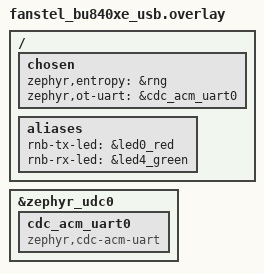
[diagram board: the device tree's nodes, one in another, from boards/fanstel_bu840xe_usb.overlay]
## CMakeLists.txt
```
# SPDX-License-Identifier: Apache-2.0

cmake_minimum_required(VERSION 3.20.0)

set(OT_NCP_VENDOR_HOOK_SOURCE_DIR ${CMAKE_CURRENT_SOURCE_DIR})

list(APPEND DTS_ROOT ${CMAKE_CURRENT_SOURCE_DIR}/../..)
list(APPEND BOARD_ROOT ${CMAKE_CURRENT_SOURCE_DIR}/../..)

string(REPLACE " " ";" OVERLAY_CONFIG_LIST "${OVERLAY_CONFIG}")
if("overlay-ot-rnb.conf" IN_LIST OVERLAY_CONFIG_LIST)
  include(${CMAKE_CURRENT_SOURCE_DIR}/../common/CMakeLists.txt)
endif()

if("overlay-usb-rnb.conf" IN_LIST OVERLAY_CONFIG_LIST)
  list(APPEND DTC_OVERLAY_FILE ${CMAKE_CURRENT_SOURCE_DIR}/boards/${BOARD}_usb.overlay)
endif()

include(CheckGit.cmake)
CheckCoprocessorGitSetup()

find_package(Zephyr REQUIRED HINTS $ENV{ZEPHYR_BASE})
project(coprocessor)

target_sources(app PRIVATE src/main.c src/nrf_802154_radio_wrapper.c ${CMAKE_BINARY_DIR}/generated/rnb_coprocessor_version.c)

target_include_directories_ifdef(CONFIG_REDNODEBUS app PUBLIC
  ${CMAKE_CURRENT_SOURCE_DIR}/../common/src)
target_sources_ifdef(CONFIG_REDNODEBUS app PRIVATE
  ${CMAKE_CURRENT_SOURCE_DIR}/../common/src/rnb_leds.c
  ${CMAKE_CURRENT_SOURCE_DIR}/../common/src/rnb_pa_lna.c)

target_include_directories(app PUBLIC ${CMAKE_CURRENT_SOURCE_DIR}/../../include)
```

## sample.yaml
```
sample:
  name: RNB OT Co-Processor
  description: RedNodeBus OpenThread Co-Processor
tests:
  sample.coprocessor.rnb.usb:
    platform_allow: nrf52833dk_nrf52833 nrf52840dk_nrf52840 nrf52840dongle_nrf52840 qorvo_dwm3001c_dev rnl_w1 fanstel_bu840xe fanstel_bt840
    integration_platforms:
      - nrf52833dk_nrf52833
      - nrf52840dk_nrf52840
      - nrf52840dongle_nrf52840
      - qorvo_dwm3001c_dev
      - rnl_w1
      - fanstel_bu840xe
    extra_args: CONF_FILE=prj.conf
                OVERLAY_CONFIG=overlay-ot-rnb.conf;overlay-vendor_hook-rnb.conf;overlay-usb-rnb.conf
    build_only: true
    tags: ci_build
  sample.coprocessor.rnb.ranging_diagnostic.usb:
    platform_allow: nrf52833dk_nrf52833 nrf52840dk_nrf52840 nrf52840dongle_nrf52840 qorvo_dwm3001c_dev rnl_w1 fanstel_bu840xe fanstel_bt840
    integration_platforms:
      - nrf52833dk_nrf52833
      - nrf52840dk_nrf52840
      - nrf52840dongle_nrf52840
      - qorvo_dwm3001c_dev
      - rnl_w1
    extra_args: CONF_FILE=prj.conf
                OVERLAY_CONFIG=overlay-ot-rnb.conf;overlay-vendor_hook-rnb.conf;overlay-usb-rnb.conf;../common/overlay-rnb-ranging-diagnostic.conf
    build_only: true
    tags: ci_build
  sample.coprocessor.rnb.usb.mcuboot:
    platform_allow: nrf52833dk_nrf52833 nrf52840dk_nrf52840 qorvo_dwm3001c_dev rnl_w1 fanstel_bu840xe fanstel_bt840
    integration_platforms:
      - nrf52833dk_nrf52833
      - nrf52840dk_nrf52840
      - qorvo_dwm3001c_dev
      - rnl_w1
      - fanstel_bu840xe
    extra_args: CONF_FILE=prj_mcuboot.conf
                OVERLAY_CONFIG=overlay-ot-rnb.conf;overlay-vendor_hook-rnb.conf;overlay-usb-rnb.conf
    build_only: true
    tags: ci_private_build
  sample.coprocessor.rnb.ranging_diagnostic.usb.mcuboot:
    platform_allow: nrf52833dk_nrf52833 nrf52840dk_nrf52840 qorvo_dwm3001c_dev rnl_w1 fanstel_bu840xe fanstel_bt840
    integration_platforms:
      - nrf52833dk_nrf52833
      - nrf52840dk_nrf52840
      - qorvo_dwm3001c_dev
      - rnl_w1
    extra_args: CONF_FILE=prj_mcuboot.conf
                OVERLAY_CONFIG=overlay-ot-rnb.conf;overlay-vendor_hook-rnb.conf;overlay-usb-rnb.conf;../common/overlay-rnb-ranging-diagnostic.conf
    build_only: true
    tags: ci_private_build
  sample.coprocessor.rnb.uart:
    platform_allow: nrf52833dk_nrf52833 nrf52840dk_nrf52840 fanstel_bt840
    integration_platforms:
      - nrf52833dk_nrf52833
      - nrf52840dk_nrf52840
      - fanstel_bt840
    extra_args: CONF_FILE=prj.conf
                OVERLAY_CONFIG=overlay-ot-rnb.conf;overlay-vendor_hook-rnb.conf
    build_only: true
    tags: ci_build
  sample.coprocessor.rnb.uart.mcuboot:
    platform_allow: nrf52833dk_nrf52833 nrf52840dk_nrf52840 fanstel_bt840
    integration_platforms:
      - nrf52833dk_nrf52833
      - nrf52840dk_nrf52840
      - fanstel_bt840
    extra_args: CONF_FILE=prj_mcuboot.conf
                OVERLAY_CONFIG=overlay-ot-rnb.conf;overlay-vendor_hook-rnb.conf
    build_only: true
    tags: ci_private_build
```

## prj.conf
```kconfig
# Copyright (c) 2023 RedNodeLabs.

# Set OpenThread NCP architecture
CONFIG_OPENTHREAD_COPROCESSOR=y
CONFIG_OPENTHREAD_COPROCESSOR_RCP=y

# Logging
CONFIG_LOG=y
CONFIG_OT_COPROCESSOR_LOG_LEVEL_ERR=y
CONFIG_LOG_MAX_LEVEL=1
CONFIG_OPENTHREAD_DEBUG=y
CONFIG_OPENTHREAD_LOG_LEVEL_CRIT=y
CONFIG_LOG_BACKEND_SPINEL=y
CONFIG_LOG_BACKEND_RTT=n
CONFIG_LOG_BACKEND_UART=n
CONFIG_BOOT_BANNER=n

# Increase logging thread stack size due to Spinel backend needs
CONFIG_LOG_PROCESS_THREAD_STACK_SIZE=2048

# Enable OpenThread features set
CONFIG_OPENTHREAD_NORDIC_LIBRARY_MASTER=y

CONFIG_NET_L2_OPENTHREAD=y

# Generic networking options
CONFIG_NETWORKING=y

CONFIG_MBEDTLS_SHA1_C=n
CONFIG_FPU=y
```

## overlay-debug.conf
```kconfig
#
# Copyright (c) 2022 Nordic Semiconductor
#
# SPDX-License-Identifier: LicenseRef-Nordic-5-Clause
CONFIG_LOG=y
CONFIG_NET_LOG=y
CONFIG_LOG_BACKEND_SHOW_COLOR=n

# Option for configuring log level in whole Zephyr
CONFIG_LOG_MAX_LEVEL=3

# Enable RTT logging backend
CONFIG_USE_SEGGER_RTT=y
CONFIG_LOG_BACKEND_RTT=y

# Disable Spinel logging backend
CONFIG_LOG_BACKEND_SPINEL=n

CONFIG_REDNODEBUS_DRIVER_LOG_LEVEL_WRN=y
CONFIG_REDNODERANGING_DRIVER_LOG_LEVEL_WRN=y

CONFIG_OPENTHREAD_DEBUG=y
CONFIG_OPENTHREAD_L2_DEBUG=y
CONFIG_OPENTHREAD_LOG_LEVEL_INFO=y
# CONFIG_OPENTHREAD_LOG_LEVEL_DEBG=y
CONFIG_OPENTHREAD_L2_LOG_LEVEL_INF=y
# CONFIG_OPENTHREAD_L2_LOG_LEVEL_DBG=y

CONFIG_ASSERT=y
CONFIG_WATCHDOG=n
CONFIG_ASSERT_NO_COND_INFO=y
```

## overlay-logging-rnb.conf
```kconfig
#
# Copyright (c) 2022 RedNodeLabs
#

CONFIG_LOG=y
CONFIG_NET_LOG=y

# Disable Spinel logging backend
CONFIG_LOG_BACKEND_SPINEL=y

# Enable RTT logging backend
CONFIG_USE_SEGGER_RTT=n
CONFIG_LOG_BACKEND_RTT=n

# Option for configuring log level in whole Zephyr
CONFIG_LOG_MAX_LEVEL=3

# Option for configuring log level in sample module
#CONFIG_OT_COPROCESSOR_LOG_LEVEL_WRN=y

# Option for configuring log level in OpenThread
#CONFIG_OPENTHREAD_LOG_LEVEL_WARN=y

# Disable logging from net config library
CONFIG_NET_CONFIG_LOG_LEVEL_OFF=y

# Adjust log strdup settings
CONFIG_LOG_STRDUP_BUF_COUNT=32
CONFIG_LOG_STRDUP_MAX_STRING=128
```

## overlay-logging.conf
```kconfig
#
# Copyright (c) 2020 Nordic Semiconductor
#
# SPDX-License-Identifier: LicenseRef-Nordic-5-Clause
CONFIG_LOG=y
CONFIG_NET_LOG=y
CONFIG_LOG_BACKEND_SHOW_COLOR=n

# Option for configuring log level in whole Zephyr
CONFIG_LOG_MAX_LEVEL=3

CONFIG_REDNODEBUS_DRIVER_LOG_LEVEL_WRN=y

CONFIG_OPENTHREAD_DEBUG=y
CONFIG_OPENTHREAD_L2_DEBUG=y
CONFIG_OPENTHREAD_LOG_LEVEL_INFO=y
# CONFIG_OPENTHREAD_LOG_LEVEL_DEBG=y
CONFIG_OPENTHREAD_L2_LOG_LEVEL_INF=y
# CONFIG_OPENTHREAD_L2_LOG_LEVEL_DBG=y
```

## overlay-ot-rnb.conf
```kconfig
#
# Copyright (c) 2022 RedNodeLabs
#

# RedNodeBus
CONFIG_NRF_REDNODEBUS_EVENT_BUFFERS=64
CONFIG_NRF_REDNODEBUS_RX_BUFFERS=64
CONFIG_REDNODERANGING=n

# Zephyr
CONFIG_NET_TC_THREAD_PREEMPTIVE=n
CONFIG_SYSTEM_WORKQUEUE_PRIORITY=-1
```

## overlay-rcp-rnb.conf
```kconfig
#
# Copyright (c) 2022 RedNodeLabs
#

CONFIG_OPENTHREAD_COPROCESSOR_RCP=y

# RedNodeBus specific
CONFIG_REDNODEBUS=y
CONFIG_NRF_REDNODEBUS_EVENT_BUFFERS=16
CONFIG_NRF_REDNODEBUS_RX_BUFFERS=32
```

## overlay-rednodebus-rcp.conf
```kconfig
#
# Copyright (c) 2021 Nordic Semiconductor
#
# SPDX-License-Identifier: LicenseRef-Nordic-5-Clause
#

CONFIG_OPENTHREAD_COPROCESSOR_RCP=y

# RedNodeBus specific
CONFIG_PM=y
CONFIG_PM_DEVICE=y

CONFIG_WATCHDOG=n
CONFIG_WDT_DISABLE_AT_BOOT=n

CONFIG_TEST_RANDOM_GENERATOR=n
CONFIG_XOROSHIRO_RANDOM_GENERATOR=y

CONFIG_NET_LOG=y
#CONFIG_NET_L2_IEEE802154_LOG_LEVEL_ERR=y
CONFIG_NET_L2_IEEE802154_LOG_LEVEL_INF=y

CONFIG_REDNODEBUS=y
# >> OT
CONFIG_NET_L2_IEEE802154=n
CONFIG_REDNODEBUS_EMPTY_PAYLOAD=n
CONFIG_REDNODEBUS_REDNODERANGING_DIAGNOSTIC_ENABLED=n
# <<
CONFIG_REDNODEBUS_ROLE=1
CONFIG_REDNODEBUS_COMMISSIONING=n
CONFIG_REDNODEBUS_ANCHOR_SLOT_COUNT=6
CONFIG_REDNODEBUS_TAG_SLOT_COUNT=2
CONFIG_REDNODEBUS_DRIVER_LOG_LEVEL_ERR=y
#CONFIG_REDNODEBUS_DRIVER_LOG_LEVEL_INF=y
#CONFIG_REDNODEBUS_DRIVER_LOG_LEVEL_DBG=y

#CONFIG_LOG_STRDUP_MAX_STRING=3072
#CONFIG_LOG_STRDUP_BUF_COUNT=16
#CONFIG_LOG_PROCESS_TRIGGER_THRESHOLD=0
#CONFIG_LOG_PROCESS_THREAD_SLEEP_MS=0

#CONFIG_SHELL_ARGC_MAX=16

#CONFIG_USE_SEGGER_RTT=n
#CONFIG_LOG_BACKEND_RTT=n
#CONFIG_LOG_BACKEND_UART=n

#CONFIG_SHELL_LOG_BACKEND=y
#CONFIG_SHELL_BACKEND_SERIAL=y
#CONFIG_SHELL_BACKEND_RTT=n
#CONFIG_SHELL_BACKEND_SERIAL_RX_RING_BUFFER_SIZE=128
```

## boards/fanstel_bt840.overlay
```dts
/*
 * Copyright (c) 2023 RedNodeLabs
 */

&uart0 {
	current-speed = <1000000>;
	status = "okay";
	hw-flow-control;
	interrupts = <2 4>;
};

/ {
	chosen {
		zephyr,entropy = &rng;
		zephyr,ot-uart = &uart0;
	};
};
```

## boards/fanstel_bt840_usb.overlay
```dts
/*
 * Copyright (c) 2023 RedNodeLabs
 */

/ {
	chosen {
		zephyr,entropy = &rng;
		zephyr,ot-uart = &cdc_acm_uart0;
	};
};

&zephyr_udc0 {
	cdc_acm_uart0: cdc_acm_uart0 {
		compatible = "zephyr,cdc-acm-uart";
	};
};
```

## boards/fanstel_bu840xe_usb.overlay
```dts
/*
 * Copyright (c) 2024 RedNodeLabs
 */

/ {
	chosen {
		zephyr,entropy = &rng;
		zephyr,ot-uart = &cdc_acm_uart0;
	};

	aliases {
		rnb-tx-led = &led0_red;
		rnb-rx-led = &led4_green;
	};
};

&zephyr_udc0 {
	cdc_acm_uart0: cdc_acm_uart0 {
		compatible = "zephyr,cdc-acm-uart";
	};
};
```

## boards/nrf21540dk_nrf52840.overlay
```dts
/* Copyright (c) 2020 Nordic Semiconductor ASA
 *
 * SPDX-License-Identifier: LicenseRef-Nordic-5-Clause
 */

/* Default Zephyr configuration already provides GPIO support for FEM. */

&uart0 {
	current-speed = <1000000>;
	status = "okay";
	hw-flow-control;
	interrupts = <2 4>;
};

&uart1 {
	current-speed = <1000000>;
	status = "okay";
};

/ {
	/*
	* In some default configurations within the nRF Connect SDK,
	* e.g. on nRF52840, the chosen zephyr,entropy node is &cryptocell.
	* This devicetree overlay ensures that default is overridden wherever it
	* is set, as this application uses the RNG node for entropy exclusively.
	*/
	chosen {
		zephyr,entropy = &rng;
		zephyr,ot-uart = &uart0;
	};
};
```

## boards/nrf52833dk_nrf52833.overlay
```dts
/*
 * Copyright (c) 2023 RedNodeLabs
 */

&uart0 {
	current-speed = <1000000>;
	status = "okay";
	hw-flow-control;
	interrupts = <2 4>;
};

&uart1 {
	current-speed = <1000000>;
	status = "okay";
};

/ {
	chosen {
		zephyr,entropy = &rng;
		zephyr,ot-uart = &uart0;
	};

	aliases {
		rnb-tx-led = &led0;
		rnb-rx-led = &led1;
	};
};
```

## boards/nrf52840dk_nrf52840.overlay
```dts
/*
 * Copyright (c) 2023 RedNodeLabs
 */

&uart0 {
	current-speed = <1000000>;
	status = "okay";
	hw-flow-control;
	interrupts = <2 4>;
	// tx-pin = <6>;
	// rx-pin = <8>;
	// rts-pin = <5>;
	// cts-pin = <7>;
};

&uart1 {
	current-speed = <1000000>;
	status = "okay";
};

/ {
	chosen {
		zephyr,entropy = &rng;
		zephyr,ot-uart = &uart0;
	};

	aliases {
		rnb-tx-led = &led0;
		rnb-rx-led = &led1;
	};
};
```

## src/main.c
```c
/*
 * Copyright (c) 2020 Nordic Semiconductor ASA
 *
 * SPDX-License-Identifier: LicenseRef-Nordic-5-Clause
 */
#include <logging/log.h>
#include <net/ieee802154_radio.h>
#include <zephyr/device.h>

#if defined(CONFIG_REDNODEBUS)
#include "rnb_leds.h"
#include "rnb_pa_lna.h"
#endif /* CONFIG_REDNODEBUS */

LOG_MODULE_REGISTER(coprocessor_sample, CONFIG_OT_COPROCESSOR_LOG_LEVEL);

#if defined(CONFIG_REDNODEBUS)
/* Convenience defines for RADIO */
#define REDNODEBUS_API(dev) ((const struct ieee802154_radio_api *const)(dev)->api)

static void handle_rnb_user_rxtx_signal(const struct device *dev,
					enum rednodebus_user_rxtx_signal sig,
					bool active);

static void handle_rnb_user_rxtx_signal(const struct device *dev,
					enum rednodebus_user_rxtx_signal sig,
					bool active)
{
	switch (sig)
	{
	case REDNODEBUS_USER_RX_SIGNAL:
		rnb_leds_set_tx(active);
		break;
	case REDNODEBUS_USER_TX_SIGNAL:
		rnb_leds_set_rx(active);
		break;
	default:
		break;
	}
}
#endif /* CONFIG_REDNODEBUS */

#if defined(CONFIG_REDNODEBUS_WATCHDOG)
const struct device *rnb_get_wdt(void)
{
	const struct device *wdt = DEVICE_DT_GET(DT_ALIAS(watchdog0));
	return wdt;
}
#endif /* CONFIG_REDNODEBUS_WATCHDOG */

void main(void)
{
#if defined(CONFIG_REDNODEBUS)
	int ret;

	ret = rnb_leds_init();
	if (ret != 0)
	{
		LOG_WRN("Cannot init RedNodeBus LEDs");
	}

#if defined(CONFIG_BOARD_FANSTEL_BU840XE)
	ret = rnb_pa_lna_init(true);
	if (ret != 0)
	{
		LOG_WRN("Cannot init RedNodeBus PA LNA");
	}
#endif

	const struct device *dev = device_get_binding(CONFIG_IEEE802154_NRF5_DRV_NAME);
	struct ieee802154_config ieee802154_config;

	ieee802154_config.rnb_user_rxtx_signal_handler = handle_rnb_user_rxtx_signal;
	REDNODEBUS_API(dev)->configure(dev, REDNODEBUS_CONFIG_USER_RXTX_SIGNAL_HANDLER, &ieee802154_config);
#endif /* CONFIG_REDNODEBUS */
}
```

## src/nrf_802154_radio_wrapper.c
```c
/*
 * Copyright (c) 2020 Nordic Semiconductor ASA
 *
 * SPDX-License-Identifier: LicenseRef-Nordic-5-Clause
 */
#include "nrf_802154_radio_wrapper.h"
#if !defined(CONFIG_REDNODEBUS)
#include <nrf_802154.h>
#endif
#include <device.h>
#include <net/ieee802154_radio.h>

#if !defined(CONFIG_REDNODEBUS)
static const struct device *radio_dev;
static struct ieee802154_radio_api *radio_api;

bool nrf_802154_radio_wrapper_auto_ack_get(void)
{
	return nrf_802154_auto_ack_get();
}

void nrf_802154_radio_wrapper_auto_ack_set(bool enabled)
{
	nrf_802154_auto_ack_set(enabled);
}

uint16_t nrf_802154_radio_wrapper_hw_capabilities_get(void)
{
	radio_dev = device_get_binding(CONFIG_NET_CONFIG_IEEE802154_DEV_NAME);
	__ASSERT_NO_MSG(radio_dev != NULL);

	radio_api = (struct ieee802154_radio_api *)radio_dev->api;
	__ASSERT_NO_MSG(radio_api != NULL);

	return radio_api->get_capabilities(radio_dev);
}
#endif
```

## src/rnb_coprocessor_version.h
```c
/*
 * Copyright (c) 2022 RedNodeLabs
 */

/* rnb_coprocessor_version.h */

#ifndef RNB_COPROCESSOR_VERSION_H_
#define RNB_COPROCESSOR_VERSION_H_

#ifdef __cplusplus
extern "C" {
#endif

extern const char *m_rnb_coprocessor_version;

#ifdef __cplusplus
}
#endif

#endif /* RNB_COPROCESSOR_VERSION_H_ */
```

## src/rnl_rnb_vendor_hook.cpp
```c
/*
 * Copyright (c) 2020 Nordic Semiconductor ASA
 *
 * SPDX-License-Identifier: LicenseRef-Nordic-5-Clause
 */
/**
 * @file
 *   This file shows how to implement the NCP vendor hook.
 */
#if OPENTHREAD_ENABLE_NCP_VENDOR_HOOK
#include "nrf_802154_radio_wrapper.h"
#include <logging/log.h>
#include <ncp_base.hpp>
#include <ncp_hdlc.hpp>
#include <common/new.hpp>

#include "rnb_coprocessor_version.h"

LOG_MODULE_REGISTER(ncp_sample_vendor_hook, CONFIG_OT_COPROCESSOR_LOG_LEVEL);

namespace ot
{
	namespace Ncp
	{
		static uint8_t mReceiveBuffer[300];

		otError NcpBase::VendorCommandHandler(uint8_t aHeader, unsigned int aCommand)
		{
			otError error = OT_ERROR_NONE;
			unsigned int propKey = 0;
			uint16_t len = 0;
			const uint8_t *rnbRequest = mReceiveBuffer;

			LOG_DBG("VendorCommandHandler");

			switch (aCommand)
			{
			case SPINEL_CMD_VENDOR_RNL_RNB_SEND_REQUEST:
			{
				LOG_DBG("Got SPINEL_CMD_VENDOR_RNL_RNB_SEND_REQUEST");

				SuccessOrExit(error = mDecoder.ReadUintPacked(propKey));

				if (propKey == SPINEL_PROP_VENDOR_RNL_RNB_REQUEST)
				{
					SuccessOrExit(error = mDecoder.ReadDataWithLen(rnbRequest, len));

					LOG_DBG("Got SPINEL_PROP_VENDOR_RNL_RNB_REQUEST");

					if ((len > 0) && (len <= OT_RADIO_RNL_RNB_REQUEST_MAX_SIZE))
					{
						error = otPlatRadioRnlRnbSendRequest(mInstance, (const otRadioRnlRnbRequest *)rnbRequest, len);
					}
					else
					{
						LOG_ERR("Got INVALID args");
						error = OT_ERROR_INVALID_ARGS;
					}
				}
				else
				{
					error = OT_ERROR_INVALID_ARGS;
				}
			}
			break;
			default:
				LOG_ERR("Got UNKNOWN cmd");
				error = OT_ERROR_INVALID_ARGS;
				break;
			}

		exit:
			error = WriteLastStatusFrame(aHeader, ThreadErrorToSpinelStatus(error));

			return error;
		}

		void NcpBase::VendorHandleFrameRemovedFromNcpBuffer(Spinel::Buffer::FrameTag aFrameTag)
		{
			// This method is a callback which mirrors `NcpBase::HandleFrameRemovedFromNcpBuffer()`.
			// It is called when a spinel frame is sent and removed from NCP buffer.
			//
			// (a) This can be used to track and verify that a vendor spinel frame response is
			//     delivered to the host (tracking the frame using its tag).
			//
			// (b) It indicates that NCP buffer space is now available (since a spinel frame is
			//     removed). This can be used to implement reliability mechanisms to re-send
			//     a failed spinel command response (or an async spinel frame) transmission
			//     (failed earlier due to NCP buffer being full).

			OT_UNUSED_VARIABLE(aFrameTag);
		}

		otError NcpBase::VendorGetPropertyHandler(spinel_prop_key_t aPropKey)
		{
			otError error = OT_ERROR_NONE;
			// uint16_t sendLength;
			// uint8_t header;

			switch (aPropKey)
			{
			case SPINEL_PROP_VENDOR_RNL_RNB_COPROCESSOR_VERSION:
				LOG_DBG("Got SPINEL_PROP_VENDOR_RNL_RNB_COPROCESSOR_VERSION");

				SuccessOrExit(error = mEncoder.WriteUtf8(m_rnb_coprocessor_version));
				break;
			default:
				LOG_ERR("Got UNKNOWN prop");
				error = OT_ERROR_NOT_FOUND;
				break;
			}

		exit:
			return error;
		}

		otError NcpBase::VendorSetPropertyHandler(spinel_prop_key_t aPropKey)
		{
			otError error = OT_ERROR_NONE;

			switch (aPropKey)
			{
				// TODO: Implement your set properties handlers here.
			default:
				error = OT_ERROR_NOT_FOUND;
				break;
			}

			// exit:
			return error;
		}

	} // namespace Ncp
} // namespace ot

//------------------------------------------------------------------
// When OPENTHREAD_ENABLE_NCP_VENDOR_HOOK is enabled, vendor code is
// expected to provide the `otNcpInit()` function. The reason behind
// this is to enable vendor code to define its own sub-class of
// `NcpBase` or `NcpHdlc`/`NcpSpi`.
//
// Example below show how to add a vendor sub-class over `NcpHdlc`.

class NcpVendorUart : public ot::Ncp::NcpHdlc
{
	static int SendHdlc(const uint8_t *aBuf, uint16_t aBufLength)
	{
		return mSendCallback(aBuf, aBufLength);
	}

public:
	NcpVendorUart(ot::Instance *aInstance, otNcpHdlcSendCallback aSendCallback)
	    : ot::Ncp::NcpHdlc(aInstance, &NcpVendorUart::SendHdlc)
	{
		OT_ASSERT(aSendCallback);
		mSendCallback = aSendCallback;
	}

	// Add public/private methods or member variables
private:
	static otNcpHdlcSendCallback mSendCallback;
};

otNcpHdlcSendCallback NcpVendorUart::mSendCallback;

static OT_DEFINE_ALIGNED_VAR(sNcpVendorRaw, sizeof(NcpVendorUart), uint64_t);

extern "C" void otNcpHdlcInit(otInstance *aInstance, otNcpHdlcSendCallback aSendCallback)
{
	NcpVendorUart *ncpVendor = NULL;
	ot::Instance *instance = static_cast<ot::Instance *>(aInstance);

	ncpVendor = new (&sNcpVendorRaw) NcpVendorUart(instance, aSendCallback);
}
#endif
```

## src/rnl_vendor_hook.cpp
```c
/*
 * Copyright (c) 2020 Nordic Semiconductor ASA
 *
 * SPDX-License-Identifier: LicenseRef-Nordic-5-Clause
 */
/**
 * @file
 *   This file shows how to implement the NCP vendor hook.
 */
#if OPENTHREAD_ENABLE_NCP_VENDOR_HOOK
#include "nrf_802154_radio_wrapper.h"
#include <logging/log.h>
#include <ncp_base.hpp>
#include <ncp_hdlc.hpp>
#include <common/new.hpp>
#include <net/rednodebus.h>

LOG_MODULE_REGISTER(ncp_sample_vendor_hook, CONFIG_OT_COPROCESSOR_LOG_LEVEL);

namespace ot {
namespace Ncp {

static uint8_t mReceiveBuffer[300];


otError NcpBase::VendorCommandHandler(uint8_t aHeader, unsigned int aCommand)
{
    otError error = OT_ERROR_NONE;
    unsigned int propKey = 0;
    uint16_t len = 0;
    const uint8_t *rnbRequest = mReceiveBuffer;

    LOG_DBG("VendorCommandHandler");

    switch (aCommand)
    {
    case SPINEL_CMD_VENDOR_RNL_RNB_SEND_REQUEST: {
            // LOG_DBG("Got SPINEL_CMD_VENDOR_RNL_RNB_SEND_REQUEST");

            SuccessOrExit(error = mDecoder.ReadUintPacked(propKey));

            if (propKey == SPINEL_PROP_VENDOR_RNL_RNB_REQUEST)
            {
                SuccessOrExit(error = mDecoder.ReadDataWithLen(rnbRequest, len));

                // LOG_DBG("Got SPINEL_PROP_VENDOR_RNL_RNB_REQUEST with length: %u", len);

                if ((len > 0) && (len <= OT_RADIO_RNL_RNB_REQUEST_MAX_SIZE))
                {
                    error = otPlatRadioRnlRnbSendRequest(mInstance, (const otRadioRnlRnbRequest*) rnbRequest, len);
                }
                else
                {
                    error = OT_ERROR_INVALID_ARGS;
                }
            }
            else
            {
                error = OT_ERROR_INVALID_ARGS;
            }
        }
        break;
    default:
        LOG_ERR("Got UNKNOWN cmd");
        error = OT_ERROR_INVALID_ARGS;
        break;
    }

exit:
    error = WriteLastStatusFrame(aHeader, ThreadErrorToSpinelStatus(error));

    return error;
}

void NcpBase::VendorHandleFrameRemovedFromNcpBuffer(Spinel::Buffer::FrameTag aFrameTag)
{
    // This method is a callback which mirrors `NcpBase::HandleFrameRemovedFromNcpBuffer()`.
    // It is called when a spinel frame is sent and removed from NCP buffer.
    //
    // (a) This can be used to track and verify that a vendor spinel frame response is
    //     delivered to the host (tracking the frame using its tag).
    //
    // (b) It indicates that NCP buffer space is now available (since a spinel frame is
    //     removed). This can be used to implement reliability mechanisms to re-send
    //     a failed spinel command response (or an async spinel frame) transmission
    //     (failed earlier due to NCP buffer being full).

    OT_UNUSED_VARIABLE(aFrameTag);
}

otError NcpBase::VendorGetPropertyHandler(spinel_prop_key_t aPropKey)
{
    otError error = OT_ERROR_NONE;
    // uint16_t sendLength;
    // uint8_t header;

    switch (aPropKey)
    {
    case SPINEL_PROP_VENDOR_RNL_RNB_VERSION:
        LOG_DBG("Got SPINEL_PROP_VENDOR_RNL_RNB_VERSION");

        SuccessOrExit(error = mEncoder.WriteUtf8("RNL RNB version v1.0"));
        break;
    // case SPINEL_PROP_VENDOR_RNL_RNB_RAW_STATUS:
    //     LOG_DBG("Got SPINEL_PROP_VENDOR_RNL_RNB_RAW_STATUS");
    //
    //     header = SPINEL_HEADER_FLAG | SPINEL_HEADER_IID_0;
    //     sendLength = 1;
    //
    //     // Append frame header
    //     SuccessOrExit(mEncoder.BeginFrame(header, SPINEL_CMD_PROP_VALUE_IS, SPINEL_PROP_VENDOR_RNL_RNB_RAW_STATUS));
    //     SuccessOrExit(mEncoder.WriteDataWithLen(&rnbStatus, sendLength));
    //     SuccessOrExit(mEncoder.EndFrame());
    //     break;
    default:
        LOG_ERR("Got UNKNOWN prop");
        error = OT_ERROR_NOT_FOUND;
        break;
    }

exit:
    return error;
}

otError NcpBase::VendorSetPropertyHandler(spinel_prop_key_t aPropKey)
{
    otError error = OT_ERROR_NONE;

    switch (aPropKey)
    {
        // TODO: Implement your set properties handlers here.
    default:
        error = OT_ERROR_NOT_FOUND;
        break;
    }

// exit:
    return error;
}

} // namespace Ncp
} // namespace ot

//------------------------------------------------------------------
// When OPENTHREAD_ENABLE_NCP_VENDOR_HOOK is enabled, vendor code is
// expected to provide the `otNcpInit()` function. The reason behind
// this is to enable vendor code to define its own sub-class of
// `NcpBase` or `NcpHdlc`/`NcpSpi`.
//
// Example below show how to add a vendor sub-class over `NcpHdlc`.

class NcpVendorUart : public ot::Ncp::NcpHdlc
{
    static int SendHdlc(const uint8_t *aBuf, uint16_t aBufLength)
    {
        return mSendCallback(aBuf, aBufLength);
    }

public:
    NcpVendorUart(ot::Instance *aInstance, otNcpHdlcSendCallback aSendCallback)
        : ot::Ncp::NcpHdlc(aInstance, &NcpVendorUart::SendHdlc)
    {
        OT_ASSERT(aSendCallback);
        mSendCallback = aSendCallback;
    }

    // Add public/private methods or member variables
private:
    static otNcpHdlcSendCallback mSendCallback;
};

otNcpHdlcSendCallback NcpVendorUart::mSendCallback;

static OT_DEFINE_ALIGNED_VAR(sNcpVendorRaw, sizeof(NcpVendorUart), uint64_t);


extern "C" void otNcpHdlcInit(otInstance *aInstance, otNcpHdlcSendCallback aSendCallback)
{
    NcpVendorUart *ncpVendor = NULL;
    ot::Instance *instance = static_cast<ot::Instance *>(aInstance);

    ncpVendor = new (&sNcpVendorRaw) NcpVendorUart(instance, aSendCallback);
}
#endif
```
